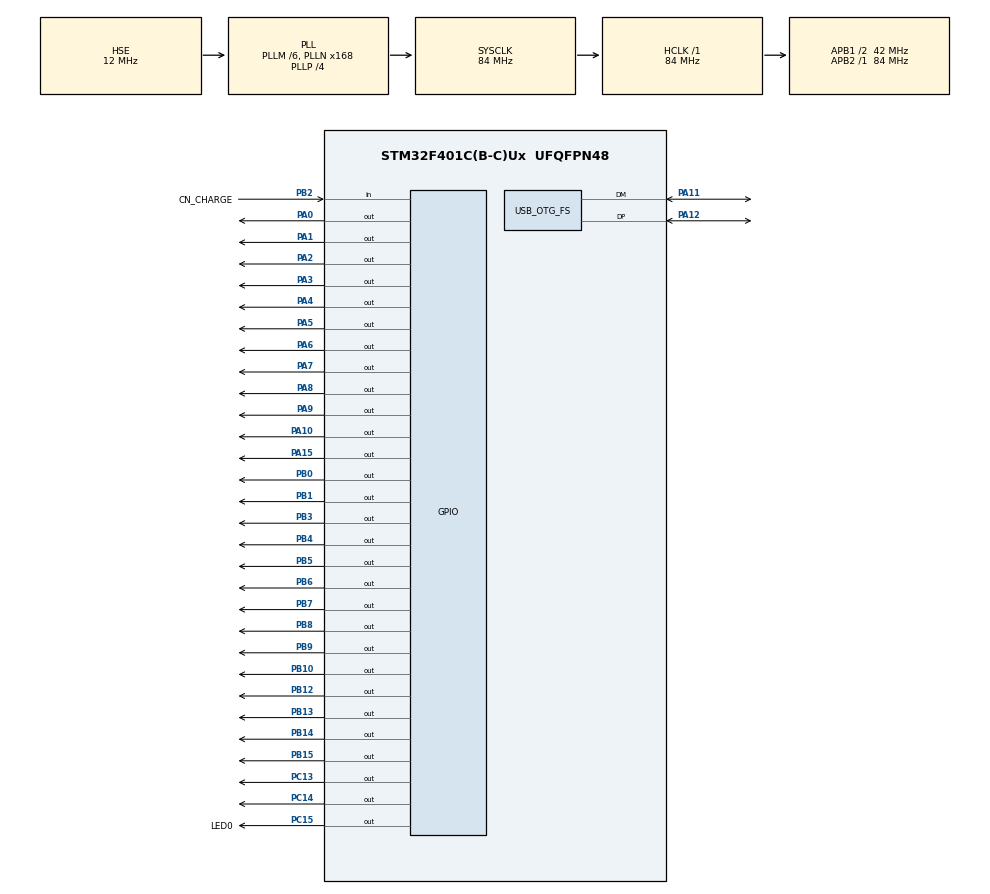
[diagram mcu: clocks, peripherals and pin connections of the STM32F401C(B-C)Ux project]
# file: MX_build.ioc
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FREERTOS.Tasks01=defaultTask,24,128,StartDefaultTask,Default,NULL,Dynamic,NULL,NULL
Mcu.Family=STM32F4
Mcu.Name=STM32F401C(B-C)Ux
Mcu.Package=UFQFPN48
NVIC.OTG_FS_IRQn=true\:5\:0\:false\:false\:true\:true\:false\:true
NVIC.PriorityGroup=NVIC_PRIORITYGROUP_4
NVIC.TIM1_TRG_COM_TIM11_IRQn=true\:15\:0\:false\:false\:true\:false\:false\:true
NVIC.TimeBase=TIM1_TRG_COM_TIM11_IRQn
NVIC.TimeBaseIP=TIM11
PA0-WKUP.PinState=GPIO_PIN_SET
PA0-WKUP.Signal=GPIO_Output
PA1.PinState=GPIO_PIN_SET
PA1.Signal=GPIO_Output
PA10.PinState=GPIO_PIN_SET
PA10.Signal=GPIO_Output
PA11.Mode=Device_Only
PA11.Signal=USB_OTG_FS_DM
PA12.Mode=Device_Only
PA12.Signal=USB_OTG_FS_DP
PA13.Mode=Serial_Wire
PA13.Signal=SYS_JTMS-SWDIO
PA14.Mode=Serial_Wire
PA14.Signal=SYS_JTCK-SWCLK
PA15.PinState=GPIO_PIN_SET
PA15.Signal=GPIO_Output
PA2.PinState=GPIO_PIN_SET
PA2.Signal=GPIO_Output
PA3.PinState=GPIO_PIN_SET
PA3.Signal=GPIO_Output
PA4.PinState=GPIO_PIN_SET
PA4.Signal=GPIO_Output
PA5.PinState=GPIO_PIN_SET
PA5.Signal=GPIO_Output
PA6.PinState=GPIO_PIN_SET
PA6.Signal=GPIO_Output
PA7.PinState=GPIO_PIN_SET
PA7.Signal=GPIO_Output
PA8.PinState=GPIO_PIN_SET
PA8.Signal=GPIO_Output
PA9.PinState=GPIO_PIN_SET
PA9.Signal=GPIO_Output
PB0.PinState=GPIO_PIN_SET
PB0.Signal=GPIO_Output
PB1.PinState=GPIO_PIN_SET
PB1.Signal=GPIO_Output
PB10.PinState=GPIO_PIN_SET
PB10.Signal=GPIO_Output
PB12.PinState=GPIO_PIN_SET
PB12.Signal=GPIO_Output
PB13.PinState=GPIO_PIN_SET
PB13.Signal=GPIO_Output
PB14.PinState=GPIO_PIN_SET
PB14.Signal=GPIO_Output
PB15.PinState=GPIO_PIN_SET
PB15.Signal=GPIO_Output
PB2.GPIO_Label=CN_CHARGE
PB2.GPIO_PuPd=GPIO_PULLUP
PB2.Signal=GPIO_Input
PB3.PinState=GPIO_PIN_SET
PB3.Signal=GPIO_Output
PB4.PinState=GPIO_PIN_SET
PB4.Signal=GPIO_Output
PB5.PinState=GPIO_PIN_SET
PB5.Signal=GPIO_Output
PB6.PinState=GPIO_PIN_SET
PB6.Signal=GPIO_Output
PB7.PinState=GPIO_PIN_SET
PB7.Signal=GPIO_Output
PB8.PinState=GPIO_PIN_SET
PB8.Signal=GPIO_Output
PB9.PinState=GPIO_PIN_SET
PB9.Signal=GPIO_Output
PC13-ANTI_TAMP.PinState=GPIO_PIN_SET
PC13-ANTI_TAMP.Signal=GPIO_Output
PC14-OSC32_IN.PinState=GPIO_PIN_SET
PC14-OSC32_IN.Signal=GPIO_Output
PC15-OSC32_OUT.GPIO_Label=LED0
PC15-OSC32_OUT.PinState=GPIO_PIN_SET
PC15-OSC32_OUT.Signal=GPIO_Output
PH0\ -\ OSC_IN.Mode=HSE-External-Oscillator
PH0\ -\ OSC_IN.Signal=RCC_OSC_IN
PH1\ -\ OSC_OUT.Mode=HSE-External-Oscillator
PH1\ -\ OSC_OUT.Signal=RCC_OSC_OUT
ProjectManager.HeapSize=0x200
ProjectManager.StackSize=0x400
ProjectManager.TargetToolchain=MDK-ARM V5.32
RCC.48MHZClocksFreq_Value=48000000
RCC.AHBFreq_Value=84000000
RCC.APB1CLKDivider=RCC_HCLK_DIV2
RCC.APB1Freq_Value=42000000
RCC.APB1TimFreq_Value=84000000
RCC.APB2Freq_Value=84000000
RCC.APB2TimFreq_Value=84000000
RCC.CortexFreq_Value=84000000
RCC.HCLKFreq_Value=84000000
RCC.HSE_VALUE=12000000
RCC.HSI_VALUE=16000000
RCC.LSE_VALUE=32768
RCC.PLLM=6
RCC.PLLN=168
RCC.PLLP=RCC_PLLP_DIV4
RCC.PLLQ=7
RCC.SYSCLKFreq_VALUE=84000000
RCC.SYSCLKSource=RCC_SYSCLKSOURCE_PLLCLK
RCC.VCOOutputFreq_Value=336000000
USB_DEVICE.CLASS_NAME_FS=CDC
USB_DEVICE.VirtualMode=Cdc
USB_DEVICE.VirtualModeFS=Cdc_FS
USB_OTG_FS.VirtualMode=Device_Only
VP_FREERTOS_VS_CMSIS_V2.Mode=CMSIS_V2
VP_SYS_VS_tim11.Mode=TIM11
VP_USB_DEVICE_VS_USB_DEVICE_CDC_FS.Mode=CDC_FS
board=custom

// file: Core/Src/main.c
/* USER CODE BEGIN Header */
/**
  ******************************************************************************
  * @file           : main.c
  * @brief          : Main program body
  ******************************************************************************
  * @attention
  *
  * <h2><center>&copy; Copyright (c) 2022 STMicroelectronics.
  * All rights reserved.</center></h2>
  *
  * This software component is licensed by ST under Ultimate Liberty license
  * SLA0044, the "License"; You may not use this file except in compliance with
  * the License. You may obtain a copy of the License at:
  *                             www.st.com/SLA0044
  *
  ******************************************************************************
  */
/* USER CODE END Header */
#include "main.h"
#include "cmsis_os.h"
#include "usb_device.h"
#include "gpio.h"

void SystemClock_Config(void);
void MX_FREERTOS_Init(void);

int main(void)
{

  /* MCU Configuration--------------------------------------------------------*/

  /* Reset of all peripherals, Initializes the Flash interface and the Systick. */
  HAL_Init();

  /* Configure the system clock */
  SystemClock_Config();

  /* Initialize all configured peripherals */
  MX_GPIO_Init();

  /* Init scheduler */
  osKernelInitialize();  /* Call init function for freertos objects (in freertos.c) */
  MX_FREERTOS_Init();
  /* Start scheduler */
  osKernelStart();

  /* We should never get here as control is now taken by the scheduler */
  /* Infinite loop */
  while (1)
  {

  }
}

void SystemClock_Config(void)
{
  RCC_OscInitTypeDef RCC_OscInitStruct = {0};
  RCC_ClkInitTypeDef RCC_ClkInitStruct = {0};

  /** Configure the main internal regulator output voltage
  */
  __HAL_RCC_PWR_CLK_ENABLE();
  __HAL_PWR_VOLTAGESCALING_CONFIG(PWR_REGULATOR_VOLTAGE_SCALE2);
  /** Initializes the RCC Oscillators according to the specified parameters
  * in the RCC_OscInitTypeDef structure.
  */
  RCC_OscInitStruct.OscillatorType = RCC_OSCILLATORTYPE_HSE;
  RCC_OscInitStruct.HSEState = RCC_HSE_ON;
  RCC_OscInitStruct.PLL.PLLState = RCC_PLL_ON;
  RCC_OscInitStruct.PLL.PLLSource = RCC_PLLSOURCE_HSE;
  RCC_OscInitStruct.PLL.PLLM = 6;
  RCC_OscInitStruct.PLL.PLLN = 168;
  RCC_OscInitStruct.PLL.PLLP = RCC_PLLP_DIV4;
  RCC_OscInitStruct.PLL.PLLQ = 7;
  if (HAL_RCC_OscConfig(&RCC_OscInitStruct) != HAL_OK)
  {
    Error_Handler();
  }
  /** Initializes the CPU, AHB and APB buses clocks
  */
  RCC_ClkInitStruct.ClockType = RCC_CLOCKTYPE_HCLK|RCC_CLOCKTYPE_SYSCLK
                              |RCC_CLOCKTYPE_PCLK1|RCC_CLOCKTYPE_PCLK2;
  RCC_ClkInitStruct.SYSCLKSource = RCC_SYSCLKSOURCE_PLLCLK;
  RCC_ClkInitStruct.AHBCLKDivider = RCC_SYSCLK_DIV1;
  RCC_ClkInitStruct.APB1CLKDivider = RCC_HCLK_DIV2;
  RCC_ClkInitStruct.APB2CLKDivider = RCC_HCLK_DIV1;

  if (HAL_RCC_ClockConfig(&RCC_ClkInitStruct, FLASH_LATENCY_2) != HAL_OK)
  {
    Error_Handler();
  }
}

void HAL_TIM_PeriodElapsedCallback(TIM_HandleTypeDef *htim)
{
  if (htim->Instance == TIM11) {
    HAL_IncTick();
  }
}

void Error_Handler(void)
{
  __disable_irq();
  while (1)
  {
  }
}

/************************ (C) COPYRIGHT STMicroelectronics *****END OF FILE****/

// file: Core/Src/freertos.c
/* USER CODE BEGIN Header */
/**
  ******************************************************************************
  * File Name          : freertos.c
  * Description        : Code for freertos applications
  ******************************************************************************
  * @attention
  *
  * <h2><center>&copy; Copyright (c) 2022 STMicroelectronics.
  * All rights reserved.</center></h2>
  *
  * This software component is licensed by ST under Ultimate Liberty license
  * SLA0044, the "License"; You may not use this file except in compliance with
  * the License. You may obtain a copy of the License at:
  *                             www.st.com/SLA0044
  *
  ******************************************************************************
  */
/* USER CODE END Header */

#include "FreeRTOS.h"
#include "task.h"
#include "main.h"
#include "cmsis_os.h"

/* USER CODE BEGIN Includes */
#include "app.h"
/* USER CODE END Includes */

/* Definitions for defaultTask */
osThreadId_t defaultTaskHandle;
const osThreadAttr_t defaultTask_attributes = {
  .name = "defaultTask",
  .stack_size = 128 * 4,
  .priority = (osPriority_t) osPriorityNormal,
};

void StartDefaultTask(void *argument);

extern void MX_USB_DEVICE_Init(void);
void MX_FREERTOS_Init(void); /* (MISRA C 2004 rule 8.1) */

void MX_FREERTOS_Init(void) {

  /* Create the thread(s) */
  /* creation of defaultTask */
  defaultTaskHandle = osThreadNew(StartDefaultTask, NULL, &defaultTask_attributes);

}

void StartDefaultTask(void *argument)
{
  /* init code for USB_DEVICE */
  MX_USB_DEVICE_Init();
  /* USER CODE BEGIN StartDefaultTask */
  /* Infinite loop */
  for(;;)
  {
		sys_init();
		osThreadTerminate(defaultTaskHandle);

  }
  /* USER CODE END StartDefaultTask */
}

/************************ (C) COPYRIGHT STMicroelectronics *****END OF FILE****/
